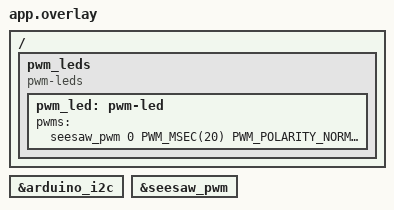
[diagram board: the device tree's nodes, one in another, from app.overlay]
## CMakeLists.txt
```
# Copyright (c) 2025 Titouan Christophe
# SPDX-License-Identifier: Apache-2.0

cmake_minimum_required(VERSION 3.13.1)
find_package(Zephyr REQUIRED HINTS $ENV{ZEPHYR_BASE})

project(pwm_rgbled LANGUAGES C)

target_sources(app PRIVATE src/main.c)
```

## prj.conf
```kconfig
CONFIG_I2C=y
CONFIG_PWM=y
CONFIG_LED=y
```

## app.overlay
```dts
seesaw_i2c: &arduino_i2c {};
#include <samples/seesaw-attiny817.dtsi>

&seesaw_pwm {
    status = "okay";
};

/ {
    pwm_leds {
        compatible = "pwm-leds";

        pwm_led: pwm-led {
            pwms = <&seesaw_pwm 0 PWM_MSEC(20) PWM_POLARITY_NORMAL>;
        };
    };
};
```

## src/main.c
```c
#include <zephyr/kernel.h>
#include <zephyr/drivers/led.h>

const struct led_dt_spec pwm_led = LED_DT_SPEC_GET(DT_NODELABEL(pwm_led));

#define MAX_BRIGHTNESS 30

int main()
{
    uint32_t t = 0;

    printk("Sample seesaw_pwm_led\n");

    while (1) {
        led_set_brightness_dt(&pwm_led, t % MAX_BRIGHTNESS);
        k_sleep(K_MSEC(50));
        t++;
    }
}
```
